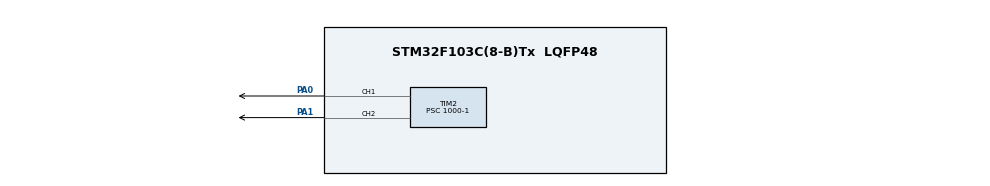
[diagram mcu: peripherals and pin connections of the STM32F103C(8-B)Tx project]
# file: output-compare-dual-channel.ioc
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Mcu.Family=STM32F1
Mcu.Name=STM32F103C(8-B)Tx
Mcu.Package=LQFP48
NVIC.PriorityGroup=NVIC_PRIORITYGROUP_4
NVIC.TIM2_IRQn=true\:0\:0\:false\:false\:true\:true\:true\:true
PA0-WKUP.Signal=S_TIM2_CH1_ETR
PA1.Signal=S_TIM2_CH2
PA13.Mode=Serial_Wire
PA13.Signal=SYS_JTMS-SWDIO
PA14.Mode=Serial_Wire
PA14.Signal=SYS_JTCK-SWCLK
PD0-OSC_IN.Mode=HSE-External-Oscillator
PD0-OSC_IN.Signal=RCC_OSC_IN
PD1-OSC_OUT.Mode=HSE-External-Oscillator
PD1-OSC_OUT.Signal=RCC_OSC_OUT
ProjectManager.HeapSize=0x200
ProjectManager.StackSize=0x400
ProjectManager.TargetToolchain=MDK-ARM V5.32
RCC.APB1Freq_Value=8000000
RCC.APB2Freq_Value=8000000
RCC.SYSCLKSource=RCC_SYSCLKSOURCE_PLLCLK
SH.S_TIM2_CH1_ETR.0=TIM2_CH1,Output Compare1 CH1
SH.S_TIM2_CH2.0=TIM2_CH2,Output Compare2 CH2
TIM2.Channel-Output\ Compare1\ CH1=TIM_CHANNEL_1
TIM2.Channel-Output\ Compare2\ CH2=TIM_CHANNEL_2
TIM2.OCMode_1=TIM_OCMODE_TOGGLE
TIM2.OCMode_2=TIM_OCMODE_TOGGLE
TIM2.Period=16000-1
TIM2.Prescaler=1000-1
TIM2.Pulse-Output\ Compare1\ CH1=4000-1
TIM2.Pulse-Output\ Compare2\ CH2=8000-1
VP_TIM2_VS_ClockSourceINT.Mode=Internal
board=custom

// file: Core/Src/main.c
/* USER CODE BEGIN Header */
/**
  ******************************************************************************
  * @file           : main.c
  * @brief          : Main program body
  ******************************************************************************
  * @attention
  *
  * Copyright (c) 2025 STMicroelectronics.
  * All rights reserved.
  *
  * This software is licensed under terms that can be found in the LICENSE file
  * in the root directory of this software component.
  * If no LICENSE file comes with this software, it is provided AS-IS.
  *
  ******************************************************************************
  */
/* USER CODE END Header */
#include "main.h"

TIM_HandleTypeDef htim2;

void SystemClock_Config(void);
static void MX_GPIO_Init(void);
static void MX_TIM2_Init(void);

/* USER CODE BEGIN 0 */
void HAL_TIM_OC_DelayElapsedCallback(TIM_HandleTypeDef *htim)
{
	if(htim->Instance == TIM2){
		if(htim->Channel== HAL_TIM_ACTIVE_CHANNEL_1){
			uint16_t comp = __HAL_TIM_GetCompare(htim,TIM_CHANNEL_1);
			__HAL_TIM_SetCompare(htim,TIM_CHANNEL_1,(comp<16000-1)?(comp+=4000):(4000-1));
		}
		else if(htim->Channel== HAL_TIM_ACTIVE_CHANNEL_2){
			uint16_t comp = __HAL_TIM_GetCompare(htim,TIM_CHANNEL_2);
			__HAL_TIM_SetCompare(htim,TIM_CHANNEL_2,(comp<16000-1)?(comp+=8000):(8000-1));
		}
	}
}
/* USER CODE END 0 */

int main(void)
{

  /* MCU Configuration--------------------------------------------------------*/

  /* Reset of all peripherals, Initializes the Flash interface and the Systick. */
  HAL_Init();

  /* Configure the system clock */
  SystemClock_Config();

  /* Initialize all configured peripherals */
  MX_GPIO_Init();
  MX_TIM2_Init();
  /* USER CODE BEGIN 2 */
	HAL_TIM_OC_Start_IT(&htim2, TIM_CHANNEL_1);
	HAL_TIM_OC_Start_IT(&htim2, TIM_CHANNEL_2);
  /* USER CODE END 2 */

  /* Infinite loop */
  while (1)
  {

  }
}

void SystemClock_Config(void)
{
  RCC_OscInitTypeDef RCC_OscInitStruct = {0};
  RCC_ClkInitTypeDef RCC_ClkInitStruct = {0};

  /** Initializes the RCC Oscillators according to the specified parameters
  * in the RCC_OscInitTypeDef structure.
  */
  RCC_OscInitStruct.OscillatorType = RCC_OSCILLATORTYPE_HSI;
  RCC_OscInitStruct.HSIState = RCC_HSI_ON;
  RCC_OscInitStruct.HSICalibrationValue = RCC_HSICALIBRATION_DEFAULT;
  RCC_OscInitStruct.PLL.PLLState = RCC_PLL_ON;
  RCC_OscInitStruct.PLL.PLLSource = RCC_PLLSOURCE_HSI_DIV2;
  RCC_OscInitStruct.PLL.PLLMUL = RCC_PLL_MUL2;
  if (HAL_RCC_OscConfig(&RCC_OscInitStruct) != HAL_OK)
  {
    Error_Handler();
  }

  /** Initializes the CPU, AHB and APB buses clocks
  */
  RCC_ClkInitStruct.ClockType = RCC_CLOCKTYPE_HCLK|RCC_CLOCKTYPE_SYSCLK
                              |RCC_CLOCKTYPE_PCLK1|RCC_CLOCKTYPE_PCLK2;
  RCC_ClkInitStruct.SYSCLKSource = RCC_SYSCLKSOURCE_PLLCLK;
  RCC_ClkInitStruct.AHBCLKDivider = RCC_SYSCLK_DIV1;
  RCC_ClkInitStruct.APB1CLKDivider = RCC_HCLK_DIV1;
  RCC_ClkInitStruct.APB2CLKDivider = RCC_HCLK_DIV1;

  if (HAL_RCC_ClockConfig(&RCC_ClkInitStruct, FLASH_LATENCY_0) != HAL_OK)
  {
    Error_Handler();
  }
}

static void MX_TIM2_Init(void)
{

  TIM_ClockConfigTypeDef sClockSourceConfig = {0};
  TIM_MasterConfigTypeDef sMasterConfig = {0};
  TIM_OC_InitTypeDef sConfigOC = {0};

  htim2.Instance = TIM2;
  htim2.Init.Prescaler = 1000-1;
  htim2.Init.CounterMode = TIM_COUNTERMODE_UP;
  htim2.Init.Period = 16000-1;
  htim2.Init.ClockDivision = TIM_CLOCKDIVISION_DIV1;
  htim2.Init.AutoReloadPreload = TIM_AUTORELOAD_PRELOAD_DISABLE;
  if (HAL_TIM_Base_Init(&htim2) != HAL_OK)
  {
    Error_Handler();
  }
  sClockSourceConfig.ClockSource = TIM_CLOCKSOURCE_INTERNAL;
  if (HAL_TIM_ConfigClockSource(&htim2, &sClockSourceConfig) != HAL_OK)
  {
    Error_Handler();
  }
  if (HAL_TIM_OC_Init(&htim2) != HAL_OK)
  {
    Error_Handler();
  }
  sMasterConfig.MasterOutputTrigger = TIM_TRGO_RESET;
  sMasterConfig.MasterSlaveMode = TIM_MASTERSLAVEMODE_DISABLE;
  if (HAL_TIMEx_MasterConfigSynchronization(&htim2, &sMasterConfig) != HAL_OK)
  {
    Error_Handler();
  }
  sConfigOC.OCMode = TIM_OCMODE_TOGGLE;
  sConfigOC.Pulse = 4000-1;
  sConfigOC.OCPolarity = TIM_OCPOLARITY_HIGH;
  sConfigOC.OCFastMode = TIM_OCFAST_DISABLE;
  if (HAL_TIM_OC_ConfigChannel(&htim2, &sConfigOC, TIM_CHANNEL_1) != HAL_OK)
  {
    Error_Handler();
  }
  sConfigOC.Pulse = 8000-1;
  if (HAL_TIM_OC_ConfigChannel(&htim2, &sConfigOC, TIM_CHANNEL_2) != HAL_OK)
  {
    Error_Handler();
  }
  HAL_TIM_MspPostInit(&htim2);

}

static void MX_GPIO_Init(void)
{

  /* GPIO Ports Clock Enable */
  __HAL_RCC_GPIOD_CLK_ENABLE();
  __HAL_RCC_GPIOA_CLK_ENABLE();

}

void Error_Handler(void)
{
  __disable_irq();
  while (1)
  {
  }
}
